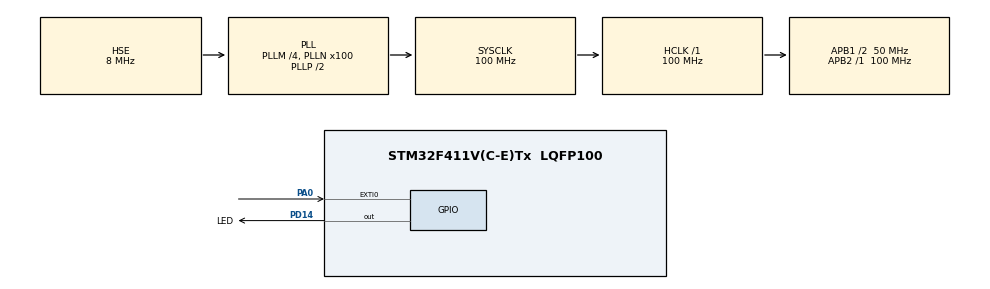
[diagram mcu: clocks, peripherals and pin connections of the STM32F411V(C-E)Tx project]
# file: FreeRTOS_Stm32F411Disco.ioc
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FREERTOS.Tasks01=defaultTask,0,128,StartDefaultTask,Default,NULL,Dynamic,NULL,NULL
FREERTOS.configUSE_NEWLIB_REENTRANT=1
Mcu.Family=STM32F4
Mcu.Name=STM32F411V(C-E)Tx
Mcu.Package=LQFP100
NVIC.EXTI0_IRQn=true\:6\:0\:true\:false\:true\:true\:true\:true\:true
NVIC.PriorityGroup=NVIC_PRIORITYGROUP_4
NVIC.TIM1_TRG_COM_TIM11_IRQn=true\:5\:0\:true\:false\:true\:false\:false\:true\:true
NVIC.TimeBase=TIM1_TRG_COM_TIM11_IRQn
NVIC.TimeBaseIP=TIM11
PA0-WKUP.Signal=GPXTI0
PA13.Mode=Serial_Wire
PA13.Signal=SYS_JTMS-SWDIO
PA14.Mode=Serial_Wire
PA14.Signal=SYS_JTCK-SWCLK
PD14.GPIO_Label=LED
PD14.GPIO_PuPd=GPIO_PULLDOWN
PD14.GPIO_Speed=GPIO_SPEED_FREQ_HIGH
PD14.Signal=GPIO_Output
PH0\ -\ OSC_IN.Mode=HSE-External-Oscillator
PH0\ -\ OSC_IN.Signal=RCC_OSC_IN
PH1\ -\ OSC_OUT.Mode=HSE-External-Oscillator
PH1\ -\ OSC_OUT.Signal=RCC_OSC_OUT
ProjectManager.HeapSize=0x200
ProjectManager.StackSize=0x400
ProjectManager.TargetToolchain=STM32CubeIDE
RCC.48MHZClocksFreq_Value=50000000
RCC.AHBFreq_Value=100000000
RCC.APB1CLKDivider=RCC_HCLK_DIV2
RCC.APB1Freq_Value=50000000
RCC.APB1TimFreq_Value=100000000
RCC.APB2Freq_Value=100000000
RCC.APB2TimFreq_Value=100000000
RCC.CortexFreq_Value=100000000
RCC.HCLKFreq_Value=100000000
RCC.HSE_VALUE=8000000
RCC.HSI_VALUE=16000000
RCC.LSE_VALUE=32768
RCC.PLLM=4
RCC.PLLN=100
RCC.PLLSourceVirtual=RCC_PLLSOURCE_HSE
RCC.SYSCLKFreq_VALUE=100000000
RCC.SYSCLKSource=RCC_SYSCLKSOURCE_PLLCLK
RCC.VCOOutputFreq_Value=200000000
VP_FREERTOS_VS_CMSIS_V1.Mode=CMSIS_V1
VP_SYS_VS_tim11.Mode=TIM11
board=custom

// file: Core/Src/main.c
/* USER CODE BEGIN Header */
/**
  ******************************************************************************
  * @file           : main.c
  * @brief          : Main program body
  ******************************************************************************
  * @attention
  *
  * Copyright (c) 2024 STMicroelectronics.
  * All rights reserved.
  *
  * This software is licensed under terms that can be found in the LICENSE file
  * in the root directory of this software component.
  * If no LICENSE file comes with this software, it is provided AS-IS.
  *
  ******************************************************************************
  */
/* USER CODE END Header */
#include "main.h"
#include "cmsis_os.h"

/* USER CODE BEGIN Includes */
#include "stdio.h"

/* USER CODE END Includes */

osThreadId defaultTaskHandle;
/* USER CODE BEGIN PV */
osThreadId 		mainTaskHandle;
osThreadId 		transmitTaskHandle;
osThreadId 		receiveTaskHandle;

xQueueHandle 	simpleQueue;
/* USER CODE END PV */

void SystemClock_Config(void);
static void MX_GPIO_Init(void);
void StartDefaultTask(void const * argument);

/* USER CODE BEGIN PFP */
void StartMainTask(void const * argument);
void TransmitterTask(void const * argument);
void ReceiverTask(void const * argument);

/* USER CODE END PFP */

/* USER CODE BEGIN 0 */
int _write(int file, char *ptr, int len)
{
	int i = 0;
	for(i = 0; i < len; i++)
	{
		ITM_SendChar(*ptr++);

	}
	return len;
}
/* USER CODE END 0 */

int main(void)
{

  /* MCU Configuration--------------------------------------------------------*/

  /* Reset of all peripherals, Initializes the Flash interface and the Systick. */
  HAL_Init();

  /* Configure the system clock */
  SystemClock_Config();

  /* Initialize all configured peripherals */
  MX_GPIO_Init();
  /* USER CODE BEGIN 2 */
  printf("Hello FreeRTOS \n");
  /* USER CODE END 2 */

  /* USER CODE BEGIN RTOS_QUEUES */
  /* add queues, ... */
  simpleQueue = xQueueCreate(5, sizeof(int));

  if(simpleQueue == 0)
  {
	  printf("Unable to create Integer Queue \n");
  }
  else
  {
	  printf("Integer Queue Created successfully \n");
  }
  /* USER CODE END RTOS_QUEUES */

  /* Create the thread(s) */
  /* definition and creation of defaultTask */

  /* USER CODE BEGIN RTOS_THREADS */
  /* add threads, ... */
  osThreadDef(mainTask, StartMainTask, osPriorityNormal, 0, 128);
  mainTaskHandle = osThreadCreate(osThread(mainTask), NULL);

  osThreadDef(transmitTask, TransmitterTask, osPriorityNormal, 0, 128);
  transmitTaskHandle = osThreadCreate(osThread(transmitTask), NULL);

  osThreadDef(receiveTask, ReceiverTask, osPriorityNormal, 0, 128);
  receiveTaskHandle = osThreadCreate(osThread(receiveTask), NULL);
  /* USER CODE END RTOS_THREADS */

  /* Start scheduler */
  osKernelStart();

  /* We should never get here as control is now taken by the scheduler */

  /* Infinite loop */
  while (1)
  {

  }
}

void SystemClock_Config(void)
{
  RCC_OscInitTypeDef RCC_OscInitStruct = {0};
  RCC_ClkInitTypeDef RCC_ClkInitStruct = {0};

  /** Configure the main internal regulator output voltage
  */
  __HAL_RCC_PWR_CLK_ENABLE();
  __HAL_PWR_VOLTAGESCALING_CONFIG(PWR_REGULATOR_VOLTAGE_SCALE1);

  /** Initializes the RCC Oscillators according to the specified parameters
  * in the RCC_OscInitTypeDef structure.
  */
  RCC_OscInitStruct.OscillatorType = RCC_OSCILLATORTYPE_HSE;
  RCC_OscInitStruct.HSEState = RCC_HSE_ON;
  RCC_OscInitStruct.PLL.PLLState = RCC_PLL_ON;
  RCC_OscInitStruct.PLL.PLLSource = RCC_PLLSOURCE_HSE;
  RCC_OscInitStruct.PLL.PLLM = 4;
  RCC_OscInitStruct.PLL.PLLN = 100;
  RCC_OscInitStruct.PLL.PLLP = RCC_PLLP_DIV2;
  RCC_OscInitStruct.PLL.PLLQ = 4;
  if (HAL_RCC_OscConfig(&RCC_OscInitStruct) != HAL_OK)
  {
    Error_Handler();
  }

  /** Initializes the CPU, AHB and APB buses clocks
  */
  RCC_ClkInitStruct.ClockType = RCC_CLOCKTYPE_HCLK|RCC_CLOCKTYPE_SYSCLK
                              |RCC_CLOCKTYPE_PCLK1|RCC_CLOCKTYPE_PCLK2;
  RCC_ClkInitStruct.SYSCLKSource = RCC_SYSCLKSOURCE_PLLCLK;
  RCC_ClkInitStruct.AHBCLKDivider = RCC_SYSCLK_DIV1;
  RCC_ClkInitStruct.APB1CLKDivider = RCC_HCLK_DIV2;
  RCC_ClkInitStruct.APB2CLKDivider = RCC_HCLK_DIV1;

  if (HAL_RCC_ClockConfig(&RCC_ClkInitStruct, FLASH_LATENCY_3) != HAL_OK)
  {
    Error_Handler();
  }
}

static void MX_GPIO_Init(void)
{
  GPIO_InitTypeDef GPIO_InitStruct = {0};

  /* GPIO Ports Clock Enable */
  __HAL_RCC_GPIOH_CLK_ENABLE();
  __HAL_RCC_GPIOA_CLK_ENABLE();
  __HAL_RCC_GPIOD_CLK_ENABLE();

  /*Configure GPIO pin Output Level */
  HAL_GPIO_WritePin(LED_GPIO_Port, LED_Pin, GPIO_PIN_RESET);

  /*Configure GPIO pin : PA0 */
  GPIO_InitStruct.Pin = GPIO_PIN_0;
  GPIO_InitStruct.Mode = GPIO_MODE_IT_RISING;
  GPIO_InitStruct.Pull = GPIO_NOPULL;
  HAL_GPIO_Init(GPIOA, &GPIO_InitStruct);

  /*Configure GPIO pin : LED_Pin */
  GPIO_InitStruct.Pin = LED_Pin;
  GPIO_InitStruct.Mode = GPIO_MODE_OUTPUT_PP;
  GPIO_InitStruct.Pull = GPIO_PULLDOWN;
  GPIO_InitStruct.Speed = GPIO_SPEED_FREQ_HIGH;
  HAL_GPIO_Init(LED_GPIO_Port, &GPIO_InitStruct);

  /* EXTI interrupt init*/
  HAL_NVIC_SetPriority(EXTI0_IRQn, 6, 0);
  HAL_NVIC_EnableIRQ(EXTI0_IRQn);

}

/* USER CODE BEGIN 4 */
void HAL_GPIO_EXTI_Callback(uint16_t GPIO_Pin)
{
	if(GPIO_PIN_SET == (HAL_GPIO_ReadPin(GPIOA, GPIO_PIN_0)))
	{
		vTaskNotifyGiveFromISR(mainTaskHandle, pdFALSE);
	}
}
/* USER CODE END 4 */

/* USER CODE BEGIN Header_StartDefaultTask */
/**
  * @brief  Function implementing the defaultTask thread.
  * @param  argument: Not used
  * @retval None
  */
void StartMainTask(void const * argument)
{
	uint32_t ulNotifyValue;

	for(;;)
	{
		ulNotifyValue = ulTaskNotifyTake(pdTRUE, 0xFFFFFFFF);
		if(ulNotifyValue != 0)
		{
			printf("Hello from Main task \n");
			HAL_GPIO_TogglePin(LED_GPIO_Port, LED_Pin);
		}
	}
}

void TransmitterTask(void const * argument)
{

}

void ReceiverTask(void const * argument)
{

}
/* USER CODE END Header_StartDefaultTask */
void StartDefaultTask(void const * argument)
{
  /* USER CODE BEGIN 5 */
  /* Infinite loop */
  for(;;)
  {}
  /* USER CODE END 5 */
}

void HAL_TIM_PeriodElapsedCallback(TIM_HandleTypeDef *htim)
{
  if (htim->Instance == TIM11) {
    HAL_IncTick();
  }
}

void Error_Handler(void)
{
  __disable_irq();
  while (1)
  {
  }
}
